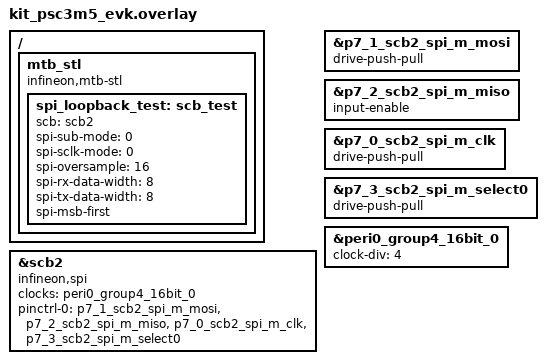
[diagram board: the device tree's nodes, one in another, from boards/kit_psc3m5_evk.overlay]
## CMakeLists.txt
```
# SPDX-License-Identifier: Apache-2.0

cmake_minimum_required(VERSION 3.20.0)

find_package(Zephyr REQUIRED HINTS $ENV{ZEPHYR_BASE})
project(post_mtb_stl_sample)

target_sources(app PRIVATE src/main.c)
```

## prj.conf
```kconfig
# POST subsystem
CONFIG_POST=y
CONFIG_POST_VENDOR_MTB_STL=y
CONFIG_POST_SHELL=y
CONFIG_POST_HALT_ON_FAILURE=n
CONFIG_POST_RUNTIME_TESTS=y

# Enable MTB-STL SPI tests
CONFIG_POST_MTB_STL_SPI_LOOPBACK=y

# Zephyr driver config
CONFIG_SPI=y

# Shell support
CONFIG_SHELL=y

# Logging
CONFIG_LOG=y
CONFIG_POST_LOG_LEVEL=4

# Shared interrupts
# Note: This config is enabled by default.
# This config enables to have multiple ISR for same irq line,
# since both test and drivers use same irq line
CONFIG_SHARED_INTERRUPTS=y
```

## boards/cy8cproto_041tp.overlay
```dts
/*
 * Copyright (c) 2025 Infineon Technologies AG,
 * or an affiliate of Infineon Technologies AG.
 *
 * SPDX-License-Identifier: Apache-2.0
 */

/*
 * Example: SPI Application — SCB portion only
 *
 * Board uses SCB1 as SPI master to an external sensor or flash.
 * STL tests the same SCB1 the application depends on.
 */

/* Board-level pinctrl for SPI */
&p1_5_scb1_spi_m_mosi {
	drive-push-pull;
};

&p1_6_scb1_spi_m_miso {
	input-enable;
};

&p1_7_scb1_spi_m_clk {
	drive-push-pull;
};

&p1_3_scb1_spi_m_select0 {
	drive-push-pull;
};

/* Application: SCB1 as SPI master */
spi1: &scb1 {
	compatible = "infineon,spi";
	status = "okay";
	pinctrl-0 = <&p1_5_scb1_spi_m_mosi &p1_6_scb1_spi_m_miso
			&p1_7_scb1_spi_m_clk &p1_3_scb1_spi_m_select0>;
	pinctrl-names = "default";
	clocks = <&peri_clk_div1>;
	#address-cells = <1>;
	#size-cells = <0>;
};

/ {
	mtb_stl: mtb_stl {
		compatible = "infineon,mtb-stl";
		status = "okay";

		/* ... DMA, TCPWM, and PWM test nodes omitted ... */

		/*
		 * SPI internal loopback
		 * C code detects "infineon,spi" on &scb1 -> SelfTest_SPI_SCB().
		 * Clock inherited from scb1's existing clocks property.
		 */
		 spi_loopback_test: scb_test {
			scb = <&scb1>;
			spi-sub-mode = <0>;
			spi-sclk-mode = <0>;
			spi-oversample = <16>;
			spi-rx-data-width = <8>;
			spi-tx-data-width = <8>;
			spi-msb-first;
		 };
	};
};
```

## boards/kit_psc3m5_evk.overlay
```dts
/*
 * SPDX-FileCopyrightText: Copyright (c) 2026 Infineon Technologies AG,
 * SPDX-FileCopyrightText: or an affiliate of Infineon Technologies AG. All rights reserved.
 *
 * SPDX-License-Identifier: Apache-2.0
 */

/*
 * Board Requirements (connections on the J5 expansion header):
 * - SPI Loop Back Test: connect J5.14 (P7.1, MOSI) -> J5.20 (P7.2, MISO)
 */

#include <zephyr/dt-bindings/gpio/gpio.h>

/* SPI internal loopback self test: scb2 as SPI master */
&scb2 {
	compatible = "infineon,spi";
	status = "okay";
	clocks = <&peri0_group4_16bit_0>;
	pinctrl-0 = <&p7_1_scb2_spi_m_mosi &p7_2_scb2_spi_m_miso
			&p7_0_scb2_spi_m_clk &p7_3_scb2_spi_m_select0>;
	pinctrl-names = "default";
	#address-cells = <1>;
	#size-cells = <0>;
};

&p7_1_scb2_spi_m_mosi {
	drive-push-pull;
};

&p7_2_scb2_spi_m_miso {
	input-enable;
};

&p7_0_scb2_spi_m_clk {
	drive-push-pull;
};

&p7_3_scb2_spi_m_select0 {
	drive-push-pull;
};

&peri0_group4_16bit_0 {
	status = "okay";
	clock-div = <4>;
};

/ {
	mtb_stl: mtb_stl {
		compatible = "infineon,mtb-stl";
		status = "okay";

		spi_loopback_test: scb_test {
			scb = <&scb2>;
			spi-sub-mode = <0>;
			spi-sclk-mode = <0>;
			spi-oversample = <16>;
			spi-rx-data-width = <8>;
			spi-tx-data-width = <8>;
			spi-msb-first;
		};
	};
};
```

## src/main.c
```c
/*
 * Copyright (c) 2026 Aerlync Labs Inc.
 * SPDX-License-Identifier: Apache-2.0
 */

#include <zephyr/kernel.h>
#include <zephyr/post/post.h>
#include <zephyr/shell/shell.h>
#include <zephyr/logging/log.h>

LOG_MODULE_REGISTER(post_spi_sample, LOG_LEVEL_INF);

int main(void)
{
	uint32_t passed;
	uint32_t failed;
	uint32_t skipped;

	printk("\n");
	printk("====================================\n");
	printk("Starting POST SPI sample application\n");
	printk("====================================\n");
	printk("\n");

	LOG_INF("POST subsystem initialized");
	LOG_INF("MTB-STL tests registered during boot");

	post_get_summary(&passed, &failed, &skipped);
	printk("POST summary: %u passed, %u failed, %u skipped\n", passed, failed, skipped);

	printk("Available shell commands:\n");
	printk("  post list   - List all registered POST tests\n");
	printk("  post run    - Run runtime POST tests\n");
	printk("  post status - Show POST test results\n");
	printk("\n");

	/* Application main loop */
	while (1) {
		k_sleep(K_SECONDS(5));
		LOG_DBG("Application running...");
	}

	return 0;
}
```
